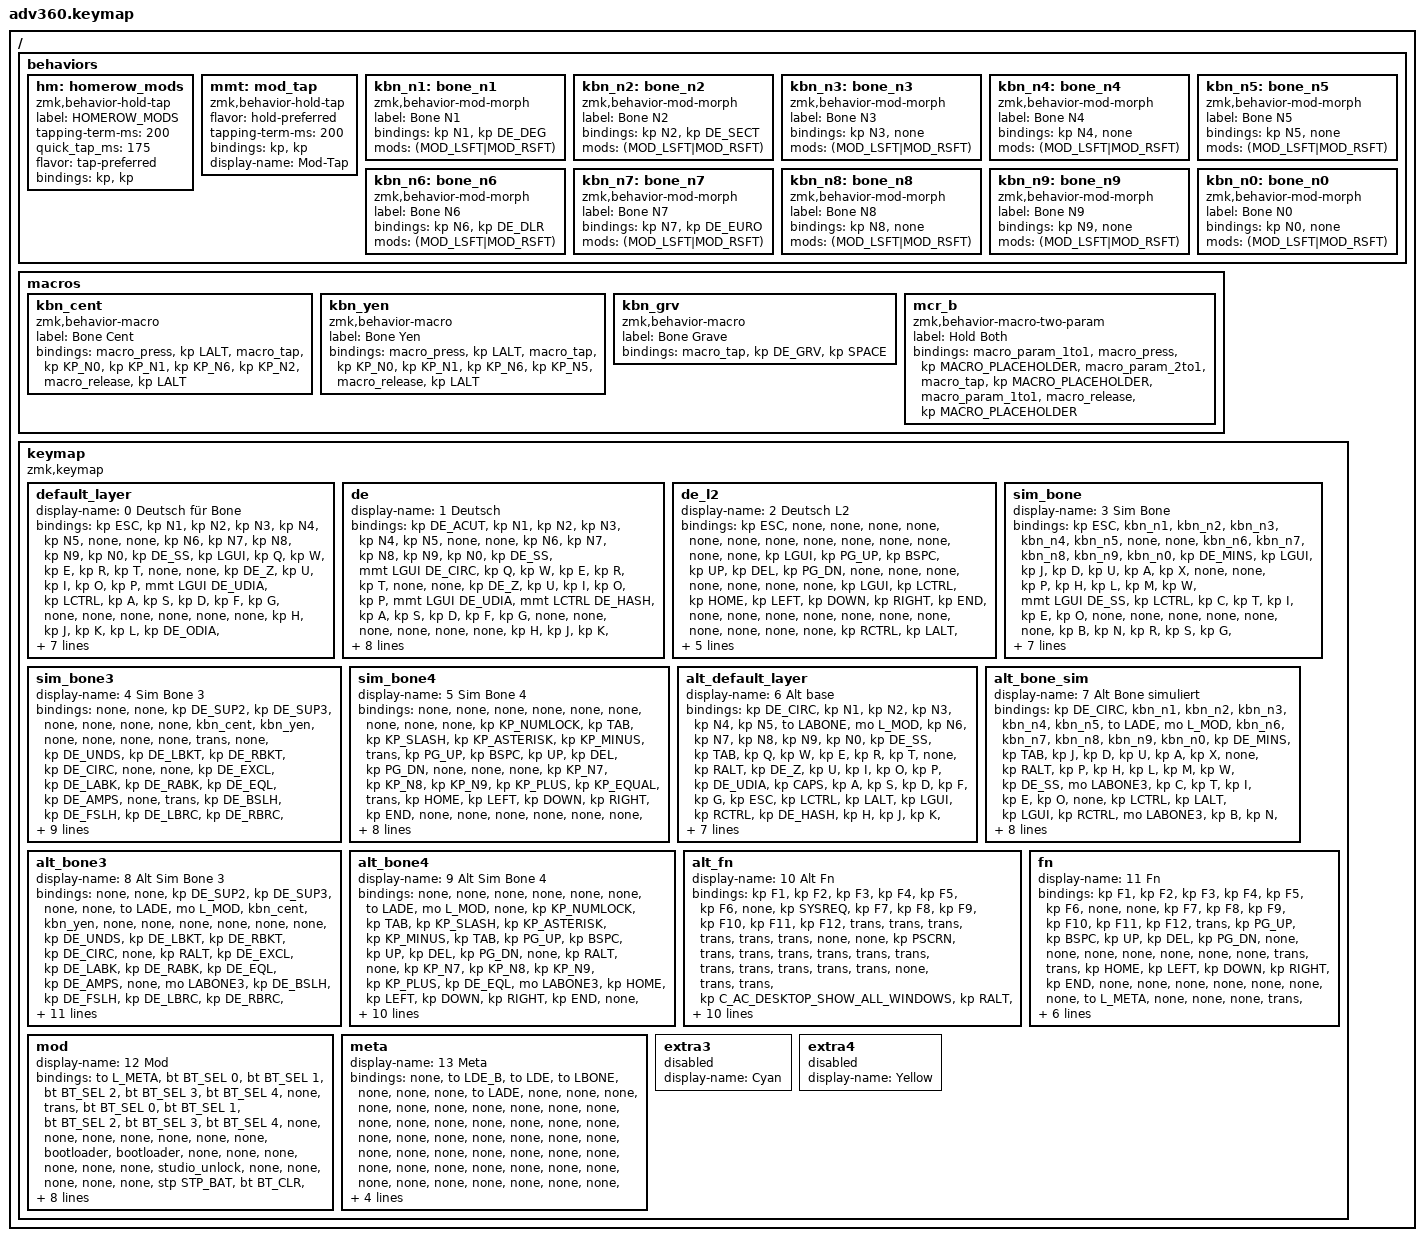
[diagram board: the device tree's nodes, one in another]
#include <behaviors.dtsi>
#include <dt-bindings/zmk/keys.h>
#include <dt-bindings/zmk/bt.h>
#include <dt-bindings/zmk/rgb.h>
#include <dt-bindings/zmk/stp.h>
#include <dt-bindings/zmk/backlight.h>
#include <dt-bindings/zmk/pointing.h>
#include "keymap_german.h"

#define LDE_B 0
#define LDE 1
#define LDE2 2
#define LBONE 3
#define LBONE3 4
#define LBONE4 5
#define LADE 6
#define LABONE 7
#define LABONE3 8
#define LABONE4 9
#define LAFN 10
#define LFN 11
#define L_MOD 12
#define L_META 13

// damit bei wiederholtem Keypress von mmt-Keys die Hold-Funktion aktiviert wird
#define QUICK_TAP_TERM 0

/ {
    behaviors {
      #include "macros.dtsi"
      #include "version.dtsi"

      hm: homerow_mods {
          compatible = "zmk,behavior-hold-tap";
          label = "HOMEROW_MODS";
          #binding-cells = <2>;
          tapping-term-ms = <200>;
          quick_tap_ms = <175>;
          flavor = "tap-preferred";
          bindings = <&kp>, <&kp>;
      };

      mmt: mod_tap {
                  compatible = "zmk,behavior-hold-tap";
                  #binding-cells = <2>;
                  flavor = "hold-preferred";
                  tapping-term-ms = <200>;
                  bindings = <&kp>, <&kp>;
                  display-name = "Mod-Tap";
              };

      // Shift+Zahl bei Sim-Bone
      kbn_n1: bone_n1 {
          compatible = "zmk,behavior-mod-morph";
          label = "Bone N1";
          #binding-cells = <0>;
          bindings = <&kp N1>, <&kp DE_DEG>;
          mods = <(MOD_LSFT|MOD_RSFT)>;
      };
      kbn_n2: bone_n2 {
          compatible = "zmk,behavior-mod-morph";
          label = "Bone N2";
          #binding-cells = <0>;
          bindings = <&kp N2>, <&kp DE_SECT>;
          mods = <(MOD_LSFT|MOD_RSFT)>;
      };
      kbn_n3: bone_n3 {
          compatible = "zmk,behavior-mod-morph";
          label = "Bone N3";
          #binding-cells = <0>;
          bindings = <&kp N3>, <&none>;
          mods = <(MOD_LSFT|MOD_RSFT)>;
      };
      kbn_n4: bone_n4 {
          compatible = "zmk,behavior-mod-morph";
          label = "Bone N4";
          #binding-cells = <0>;
          bindings = <&kp N4>, <&none>;
          mods = <(MOD_LSFT|MOD_RSFT)>;
      };
      kbn_n5: bone_n5 {
          compatible = "zmk,behavior-mod-morph";
          label = "Bone N5";
          #binding-cells = <0>;
          bindings = <&kp N5>, <&none>;
          mods = <(MOD_LSFT|MOD_RSFT)>;
      };
      kbn_n6: bone_n6 {
          compatible = "zmk,behavior-mod-morph";
          label = "Bone N6";
          #binding-cells = <0>;
          bindings = <&kp N6>, <&kp DE_DLR>;
          mods = <(MOD_LSFT|MOD_RSFT)>;
      };
      kbn_n7: bone_n7 {
          compatible = "zmk,behavior-mod-morph";
          label = "Bone N7";
          #binding-cells = <0>;
          bindings = <&kp N7>, <&kp DE_EURO>;
          mods = <(MOD_LSFT|MOD_RSFT)>;
      };
      kbn_n8: bone_n8 {
          compatible = "zmk,behavior-mod-morph";
          label = "Bone N8";
          #binding-cells = <0>;
          bindings = <&kp N8>, <&none>;
          mods = <(MOD_LSFT|MOD_RSFT)>;
      };
      kbn_n9: bone_n9 {
          compatible = "zmk,behavior-mod-morph";
          label = "Bone N9";
          #binding-cells = <0>;
          bindings = <&kp N9>, <&none>;
          mods = <(MOD_LSFT|MOD_RSFT)>;
      };
      kbn_n0: bone_n0 {
          compatible = "zmk,behavior-mod-morph";
          label = "Bone N0";
          #binding-cells = <0>;
          bindings = <&kp N0>, <&none>;
          mods = <(MOD_LSFT|MOD_RSFT)>;
      };
    };

    macros {
        // Spezielle Zeichen für Sim-Bone
        kbn_cent: kbn_cent {
            label = "Bone Cent";
            compatible = "zmk,behavior-macro";
            #binding-cells = <0>;
            bindings
                = <&macro_press &kp LALT>
                , <&macro_tap &kp KP_N0 &kp KP_N1 &kp KP_N6 &kp KP_N2>
                , <&macro_release &kp LALT>
                ;
        };
        kbn_yen: kbn_yen {
            label = "Bone Yen";
            compatible = "zmk,behavior-macro";
            #binding-cells = <0>;
            bindings
                = <&macro_press &kp LALT>
                , <&macro_tap &kp KP_N0 &kp KP_N1 &kp KP_N6 &kp KP_N5>
                , <&macro_release &kp LALT>
                ;
        };
        kbn_grv: kbn_grv {
            label = "Bone Grave";
            compatible = "zmk,behavior-macro";
            #binding-cells = <0>;
            bindings
                = <&macro_tap &kp DE_GRV &kp SPACE>
                ;
        };

        // für Combo M3, M4 in DE-für-Bone
        mcr_b: mcr_b {
            label = "Hold Both";
            compatible = "zmk,behavior-macro-two-param";
            #binding-cells = <2>;
            bindings
                = <&macro_param_1to1>
                , <&macro_press &kp MACRO_PLACEHOLDER>
                , <&macro_param_2to1>
                , <&macro_tap &kp MACRO_PLACEHOLDER>
                , <&macro_param_1to1>
                , <&macro_release &kp MACRO_PLACEHOLDER>
                ;
        };
    };

    /* Key positions:
          bindings = <
            00 01 02 03 04 05 06                         07 08 09 10 11 12 13
            14 15 16 17 18 19 20                         21 22 23 24 25 26 27
            28 29 30 31 32 33 34       35 36 37 38       39 40 41 42 43 44 45
            46 47 48 49 50 51             52 53             54 55 56 57 58 59
            60 61 62 63 64          65 66 67 68 69 70          71 72 73 74 75
          >;
    */

/*
    combos {
        compatible = "zmk,combos";

        // Zum Testen
        combo_t1 {
            layers = <0>;
            timeout-ms = <300>;
            key-positions = <35 38>;
            bindings = <&kp N1>;
        };
        combo_t2 {
            layers = <0>;
            timeout-ms = <400>;
            key-positions = <36 38>;
            bindings = <&kp N2>;
        };
        combo_t3 {
            layers = <0>;
            timeout-ms = <500>;
            key-positions = <52 38>;
            bindings = <&kp N3>;
        };
        combo_t4 {
            layers = <0>;
            timeout-ms = <600>;
            key-positions = <67 38>;
            bindings = <&kp N4>;
        };
        combo_t5 {
            layers = <0>;
            timeout-ms = <1000>;
            key-positions = <64 38>;
            bindings = <&kp N5>;
        };
        combo_t6 {
            layers = <0>;
            timeout-ms = <1000>;
            key-positions = <63 38>;
            bindings = <&kp N6>;
        };
    };
*/

  keymap {
    compatible = "zmk,keymap";

    default_layer {
      display-name = "0 Deutsch für Bone";
      bindings = <
        &kp ESC   &kp N1   &kp N2 &kp N3 &kp N4 &kp N5 &none                                                                  &none &kp N6   &kp N7 &kp N8    &kp N9   &kp N0             &kp DE_SS
        &kp LGUI  &kp Q    &kp W  &kp E  &kp R  &kp T  &none                                                                  &none &kp DE_Z &kp U  &kp I     &kp O    &kp P              &mmt LGUI DE_UDIA
        &kp LCTRL &kp A    &kp S  &kp D  &kp F  &kp G  &none              &none            &none &none &none                  &none &kp H    &kp J  &kp K     &kp L    &kp DE_ODIA        &mmt RCTRL DE_ADIA
        &kp LALT  &kp DE_Y &kp X  &kp C  &kp V  &kp B                                      &none &none                              &kp N    &kp M  &kp COMMA &kp DOT  &mmt RSHFT DE_MINS &kp LALT
        &none     &none    &none  &none  &none           &mmt LSHIFT BSPC &mmt DE_LABK TAB &none &none &lt LFN ENTER &mmt CAPS SPACE         &none  &none     &none    &none              &none
      >;
    };
    de {
      display-name = "1 Deutsch";
      bindings = <
        &kp DE_ACUT        &kp N1   &kp N2 &kp N3 &kp N4 &kp N5 &none                                                         &none &kp N6   &kp N7 &kp N8    &kp N9   &kp N0             &kp DE_SS
        &mmt LGUI DE_CIRC  &kp Q    &kp W  &kp E  &kp R  &kp T  &none                                                         &none &kp DE_Z &kp U  &kp I     &kp O    &kp P              &mmt LGUI DE_UDIA
        &mmt LCTRL DE_HASH &kp A    &kp S  &kp D  &kp F  &kp G  &none         &none        &none &none &none                  &none &kp H    &kp J  &kp K     &kp L    &kp DE_ODIA        &mmt RCTRL DE_ADIA
        &mmt LALT DE_LABK  &kp DE_Y &kp X  &kp C  &kp V  &kp B                             &none &none                              &kp N    &kp M  &kp COMMA &kp DOT  &mmt RSHFT DE_MINS &mmt RALT DE_PLUS
        &none              &none    &none  &none  &none       &mmt LSHFT BSPC &lt LDE2 TAB &none &none &lt LFN ENTER &mmt CAPS SPACE         &none  &none     &none    &none              &none
      >;
    };
    de_l2 {
      display-name = "2 Deutsch L2";
      bindings = <
        &kp ESC   &none     &none    &none    &none     &none      &none                                      &none &none &none &none &none &none     &none
        &kp LGUI  &kp PG_UP &kp BSPC &kp UP   &kp DEL   &kp PG_DN  &none                                      &none &none &none &none &none &none     &kp LGUI
        &kp LCTRL &kp HOME  &kp LEFT &kp DOWN &kp RIGHT &kp END    &none     &none  &none &none &none         &none &none &none &none &none &none     &kp RCTRL
        &kp LALT  &kp ESC   &kp TAB  &kp INS  &kp ENTER &kp K_UNDO                  &none &none                     &none &none &none &none &kp RSHFT &kp RALT
        &none     &none     &none    &none    &none                   &trans &trans &none &none &kp LSHFT &none           &none &none &none &none     &none
      >;
    };
    sim_bone {
      display-name = "3 Sim Bone";
      bindings = <
        &kp ESC   &kbn_n1 &kbn_n2 &kbn_n3     &kbn_n4     &kbn_n5     &none                                                            &none &kbn_n6  &kbn_n7  &kbn_n8   &kbn_n9 &kbn_n0      &kp DE_MINS
        &kp LGUI  &kp J   &kp D   &kp U       &kp A       &kp X       &none                                                            &none &kp P    &kp H    &kp L     &kp M   &kp W        &mmt LGUI DE_SS
        &kp LCTRL &kp C   &kp T   &kp I       &kp E       &kp O       &none          &none          &none &none &none                  &none &kp B    &kp N    &kp R     &kp S   &kp G        &mmt RCTRL Q
        &kp LALT  &kp F   &kp V   &kp DE_UDIA &kp DE_ADIA &kp DE_ODIA                               &none &none                              &kp DE_Y &kp DE_Z &kp COMMA &kp DOT &mmt RSHFT K &kp LALT
        &none     &none   &none   &none       &none                  &mmt LSHFT BSPC &lt LBONE4 TAB &none &none &lt LFN ENTER &lt LBONE3 SPACE        &none    &none     &none   &none        &none
      >;
    };
    sim_bone3 {
      display-name = "4 Sim Bone 3";
      bindings = <
        &none  &none       &kp DE_SUP2 &kp DE_SUP3 &none       &none       &none                                &none &kbn_cent   &kbn_yen    &none       &none       &none              &none
        &trans &none       &kp DE_UNDS &kp DE_LBKT &kp DE_RBKT &kp DE_CIRC &none                                &none &kp DE_EXCL &kp DE_LABK &kp DE_RABK &kp DE_EQL  &kp DE_AMPS        &none
        &trans &kp DE_BSLH &kp DE_FSLH &kp DE_LBRC &kp DE_RBRC &kp DE_STAR &none    &none &none &none &none     &none &kp DE_QUES &kp DE_LPAR &kp DE_RPAR &kp DE_MINS &kp DE_COLN        &mmt RCTRL DE_AT
        &trans &kp DE_HASH &kp DE_DLR  &kp DE_PIPE &kp DE_TILD &kbn_grv                   &none &none                 &kp DE_PLUS &kp DE_PERC &kp DE_DQT  &kp DE_SQT  &mmt RSHFT DE_SEMI &trans
        &none  &none       &none        &none      &none                    &trans &trans &none &none &trans &trans               &none       &none       &none       &none              &none
      >;
    };
    sim_bone4 {
      display-name = "5 Sim Bone 4";
      bindings = <
        &none  &none     &none    &none    &none     &none      &none                                  &none &none       &kp KP_NUMLOCK &kp TAB   &kp KP_SLASH &kp KP_ASTERISK    &kp KP_MINUS
        &trans &kp PG_UP &kp BSPC &kp UP   &kp DEL   &kp PG_DN  &none                                  &none &none       &kp KP_N7      &kp KP_N8 &kp KP_N9    &kp KP_PLUS        &kp KP_EQUAL
        &trans &kp HOME  &kp LEFT &kp DOWN &kp RIGHT &kp END    &none    &none   &none &none &none     &none &none       &kp KP_N4      &kp KP_N5 &kp KP_N6    &kp KP_COMMA       &mmt RCTRL KP_DOT
        &trans &kp ESC   &kp TAB  &kp INS  &kp ENTER &kp K_UNDO                  &none &none                 &kp DE_COLN &kp KP_N1      &kp KP_N2 &kp KP_N3    &mmt RSHFT DE_SEMI &trans
        &none  &none     &none    &none    &none                   &trans &trans &none &none &trans &kp KP_N0            &none          &none     &none        &none              &none
      >;
    };

    alt_default_layer {
      display-name = "6 Alt base";
      bindings = <
        &kp DE_CIRC &kp N1      &kp N2   &kp N3   &kp N4     &kp N5 &to LABONE                                                        &mo L_MOD   &kp N6   &kp N7 &kp N8    &kp N9      &kp N0      &kp DE_SS
        &kp TAB     &kp Q       &kp W    &kp E    &kp R      &kp T  &none                                                             &kp RALT    &kp DE_Z &kp U  &kp I     &kp O       &kp P       &kp DE_UDIA
        &kp CAPS    &kp A       &kp S    &kp D    &kp F      &kp G  &kp ESC          &kp LCTRL &kp LALT &kp LGUI  &kp RCTRL           &kp DE_HASH &kp H    &kp J  &kp K     &kp L       &kp DE_ODIA &kp DE_ADIA
        &kp LSHFT   &kp DE_Y    &kp X    &kp C    &kp V      &kp B                             &kp HOME &kp PG_UP                                 &kp N    &kp M  &kp COMMA &kp DOT     &kp DE_MINS &kp RSHFT
        &mo LAFN    &kp DE_LABK &kp CAPS &kp LEFT &kp RIGHT                 &kp BSPC &kp DEL   &kp END  &kp PG_DN &kp ENTER &kp SPACE                      &kp UP &kp DOWN  &kp DE_ACUT &kp DE_PLUS &mo LAFN
      >;
    };
    alt_bone_sim {
      display-name = "7 Alt Bone simuliert";
      bindings = <
        &kp DE_CIRC &kbn_n1     &kbn_n2  &kbn_n3     &kbn_n4     &kbn_n5     &to LADE                                                        &mo L_MOD   &kbn_n6  &kbn_n7  &kbn_n8   &kbn_n9    &kbn_n0     &kp DE_MINS
        &kp TAB     &kp J       &kp D    &kp U       &kp A       &kp X       &none                                                           &kp RALT    &kp P    &kp H    &kp L     &kp M      &kp W       &kp DE_SS
        &mo LABONE3 &kp C       &kp T    &kp I       &kp E       &kp O       &none          &kp LCTRL &kp LALT &kp LGUI  &kp RCTRL           &mo LABONE3 &kp B    &kp N    &kp R     &kp S      &kp G       &kp Q
        &kp LSHFT   &kp F       &kp V    &kp DE_UDIA &kp DE_ADIA &kp DE_ODIA                          &kp HOME &kp PG_UP                                 &kp DE_Y &kp DE_Z &kp COMMA &kp DOT    &kp K       &kp RSHFT
        &mo LAFN    &mo LABONE4 &kp CAPS &kp LEFT    &kp RIGHT                     &kp BSPC &kp DEL   &kp END  &kp PG_DN &kp ENTER &kp SPACE                      &kp UP   &kp DOWN  &kp DE_GRV &kp DE_ACUT &mo LAFN
      >;
    };
    alt_bone3 {
      display-name = "8 Alt Sim Bone 3";
      bindings = <
        &none       &none       &kp DE_SUP2 &kp DE_SUP3 &none       &none       &to LADE                                                      &mo L_MOD   &kbn_cent   &kbn_yen    &none       &none      &none       &none
        &none       &none       &kp DE_UNDS &kp DE_LBKT &kp DE_RBKT &kp DE_CIRC &none                                                         &kp RALT    &kp DE_EXCL &kp DE_LABK &kp DE_RABK &kp DE_EQL  &kp DE_AMPS &none
        &mo LABONE3 &kp DE_BSLH &kp DE_FSLH &kp DE_LBRC &kp DE_RBRC &kp DE_STAR &none        &kp LCTRL &kp LALT &kp LGUI  &kp RCTRL           &mo LABONE3 &kp DE_QUES &kp DE_LPAR &kp DE_RPAR &kp DE_MINS &kp DE_COLN &kp DE_AT
        &kp LSHFT   &kp DE_HASH &kp DE_DLR  &kp DE_PIPE &kp DE_TILD &kbn_grv                           &kp HOME &kp PG_UP                                 &kp DE_PLUS &kp DE_PERC &kp DE_DQT  &kp DE_SQT  &kp DE_SEMI &kp RSHFT
        &mo LAFN    &mo LABONE4 &kp CAPS    &kp LEFT    &kp RIGHT                     &kp BSPC &kp DEL &kp END  &kp PG_DN &kp ENTER &kp SPACE                         &kp UP      &kp DOWN    &none       &none       &mo LAFN
      >;
    };
    alt_bone4 {
      display-name = "9 Alt Sim Bone 4";
      bindings = <
        &none       &none       &none    &none      &none      &none      &to LADE                                                        &mo L_MOD   &none       &kp KP_NUMLOCK &kp TAB   &kp KP_SLASH &kp KP_ASTERISK &kp KP_MINUS
        &kp TAB     &kp PG_UP   &kp BSPC &kp UP     &kp DEL    &kp PG_DN  &none                                                           &kp RALT    &none       &kp KP_N7      &kp KP_N8 &kp KP_N9    &kp KP_PLUS     &kp DE_EQL
        &mo LABONE3 &kp HOME    &kp LEFT &kp DOWN   &kp RIGHT  &kp END    &none          &kp LCTRL &kp LALT &kp LGUI  &kp RCTRL           &mo LABONE3 &none       &kp KP_N4      &kp KP_N5 &kp KP_N6    &kp KP_DOT      &kp DOT
        &kp LSHFT   &kp ESC     &kp TAB  &kp INS    &kp ENTER  &kp K_UNDO                          &kp HOME &kp PG_UP                                 &kp DE_COLN &kp KP_N1      &kp KP_N2 &kp KP_N3    &kp DE_SEMI     &kp RSHFT
        &mo LAFN    &mo LABONE4 &kp CAPS &kp LEFT   &kp RIGHT                   &kp BSPC &kp DEL   &kp END  &kp PG_DN &kp ENTER &kp KP_N0                         &kp UP         &kp DOWN  &none        &none           &mo LAFN
      >;
    };

    alt_fn {
      display-name = "10 Alt Fn";
      bindings = <
        &kp F1 &kp F2 &kp F3 &kp F4 &kp F5 &kp F6          &none                                                                                &kp SYSREQ &kp F7    &kp F8        &kp F9        &kp F10     &kp F11  &kp F12
        &trans &trans &trans &trans &trans &trans          &none                                                                                &none      &kp PSCRN &trans        &trans        &trans      &trans   &trans
        &trans &trans &trans &trans &trans &trans          &none         &trans &trans   &kp C_AC_DESKTOP_SHOW_ALL_WINDOWS      &kp RALT        &none      &trans    &kp K_VOL_UP2 &kp K_VOL_DN2 &kp K_MUTE2 &trans   &trans
        &trans &trans &trans &trans &trans &kp PAUSE_BREAK                      &trans   &kp C_AC_DESKTOP_SHOW_ALL_WINDOWS                                 &trans    &kp K_VOL_UP  &kp K_VOL_DN  &kp K_MUTE  &trans   &trans
        &trans &trans &trans &trans &trans                        &trans &trans &kp SLCK &kp C_AC_DESKTOP_SHOW_ALL_APPLICATIONS &kp INS  &trans                      &kp C_VOL_UP  &kp C_VOL_DN  &kp C_MUTE  &kp RALT &trans
      >;
    };
    fn {
      display-name = "11 Fn";
      bindings = <
        &kp F1 &kp F2    &kp F3   &kp F4   &kp F5    &kp F6    &none                                                    &none &kp F7 &kp F8     &kp F9 &kp F10 &kp F11 &kp F12
        &trans &kp PG_UP &kp BSPC &kp UP   &kp DEL   &kp PG_DN &none                                                    &none &none  &none      &none  &none   &none   &trans
        &trans &kp HOME  &kp LEFT &kp DOWN &kp RIGHT &kp END   &none      &none &none               &none &none         &none &none  &to L_META &none  &none   &none   &trans
        &trans &kp ESC   &kp TAB  &kp INS  &kp ENTER &kp K_UNDO                 &none               &none                     &none  &none      &none  &none   &trans  &trans
        &none  &none     &none    &none    &none             &mcr_b LSHFT RSHFT &mcr_b DE_LABK RALT &none &none &none &trans         &none      &none  &none   &trans  &none
      >;
    };
    mod {
      display-name = "12 Mod";
      bindings = <
        &to L_META     &bt BT_SEL 0 &bt BT_SEL 1 &bt BT_SEL 2 &bt BT_SEL 3 &bt BT_SEL 4 &none                                                              &trans       &bt BT_SEL 0 &bt BT_SEL 1 &bt BT_SEL 2 &bt BT_SEL 3 &bt BT_SEL 4 &none
        &none          &none        &none        &none        &none        &none        &bootloader                                                        &bootloader  &none        &none        &none        &none        &none        &none
        &studio_unlock &none        &none        &none        &none        &none        &stp STP_BAT      &bt BT_CLR &bt BT_CLR &bt BT_CLR &bt BT_CLR      &stp STP_BAT &none        &none        &none        &none        &none        &none
        &none          &none        &none        &none        &macro_ver   &none                                     &none      &none                                   &none        &none        &none        &none        &none        &none
        &none          &none        &none        &bl BL_INC   &bl BL_DEC                  &rgb_ug RGB_TOG &bl BL_TOG &none      &none      &bl BL_TOG &rgb_ug RGB_TOG                &bl BL_INC   &bl BL_DEC   &none        &none        &none
      >;
    };

    meta {
      display-name = "13 Meta";
      bindings = <
        &none &to LDE_B &to LDE &to LBONE &none &none &none                                     &to LADE &none &none &none &none &none &none
        &none &none     &none   &none     &none &none &none                                     &none    &none &none &none &none &none &none
        &none &none     &none   &none     &none &none &none     &none   &none &none &none       &none    &none &none &none &none &none &none
        &none &none     &none   &none     &none &none                   &none &none                      &none &none &none &none &none &none
        &none &none     &none   &none     &none             &none &none &none &none &none &none                &none &none &none &none &none
      >;
    };

    extra3 {
      display-name = "Cyan";    
      status = "reserved";
    };

    extra4 { 
      display-name = "Yellow";    
      status = "reserved";
    };
  };
};
